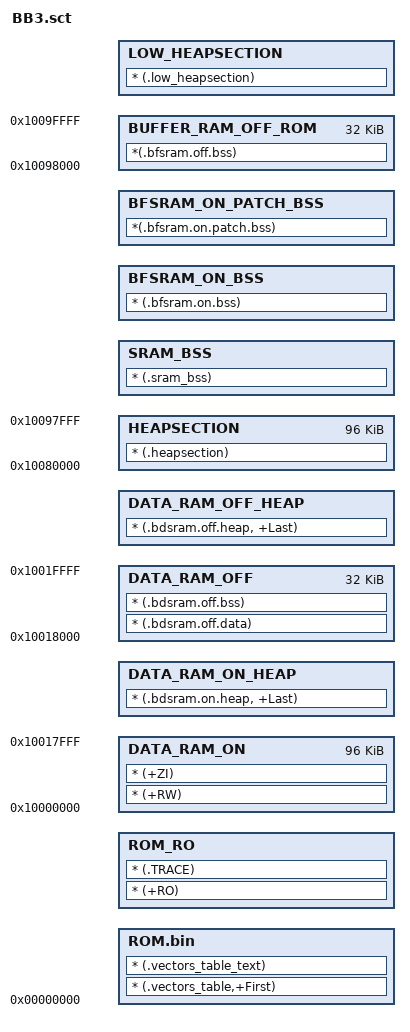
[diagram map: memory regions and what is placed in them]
#! armcc -E
#include "..\platform\inc\platform_conf.h"
; *************************************************************
; *** Scatter-Loading Description File generated by uVision ***
; *************************************************************

#define ROM_ADR         0x00000000 
#define ROM_SIZE        (512*1024)

#define DATA_RAM_ON_ADR    0x10000000 
#define DATA_RAM_ON_SIZE   (96*1024)

#define DATA_RAM_OFF_ADR    0x10018000 
#define DATA_RAM_OFF_SIZE   (32*1024)

#define BUFFER_RAM_ON_ADR  0x10080000 
#define BUFFER_RAM_ON_SIZE (96*1024)

#define BUFFER_RAM_OFF_ADR  0x10098000 
#define BUFFER_RAM_OFF_SIZE (32*1024)

#define FLASH_ADR       0x00800000 
#define FLASH_SIZE      (8*1024*1024)

LOAD_ROM ROM_ADR ROM_SIZE
{
    ROM.bin ROM_ADR
    {
        * (.vectors_table,+First)
        * (.vectors_table_text)
    }
 
    ROM_RO +0 ALIGN 0x100
    {
        * (+RO)
		* (.TRACE)
    }

    DATA_RAM_ON DATA_RAM_ON_ADR DATA_RAM_ON_SIZE
    {
        * (+RW)
		* (+ZI)
    }
	
	DATA_RAM_ON_HEAP +0
	{
		* (.bdsram.on.heap, +Last)
	}
	
	DATA_RAM_OFF DATA_RAM_OFF_ADR DATA_RAM_OFF_SIZE
    {
        * (.bdsram.off.data)
		* (.bdsram.off.bss)	
    }
	
	DATA_RAM_OFF_HEAP +0
	{
		* (.bdsram.off.heap, +Last)
	}
	
	HEAPSECTION BUFFER_RAM_ON_ADR BUFFER_RAM_ON_SIZE
    {		
	    * (.heapsection)
    }
	SRAM_BSS +0 ALIGN 0x04
	{		
		* (.sram_bss)
	}
	BFSRAM_ON_BSS +0 ALIGN 0x04
	{
		* (.bfsram.on.bss)
	}
	BFSRAM_ON_PATCH_BSS +0 ALIGN 0x04
	{
		*(.bfsram.on.patch.bss)	
	}

	BUFFER_RAM_OFF_ROM  BUFFER_RAM_OFF_ADR BUFFER_RAM_OFF_SIZE
	{
		*(.bfsram.off.bss)
	}	
    LOW_HEAPSECTION +0 ALIGN 0x04
    {
        * (.low_heapsection)
    }
}

#define ROM_TRACE_ADR   0x08000000
#define ROM_TRACE_SIZE  (128*1024)

;LOAD_ROM_TRACE ROM_TRACE_ADR ROM_TRACE_SIZE
;{ 
    ;ROM.trace ROM_TRACE_ADR ROM_TRACE_SIZE
    ;{ 
        ;* (.TRACE) 
    ;}
;}
